# M460 register map
File version: 1.0
Registers are 32-bit, read-write, reset 0x0 unless marked. A register's access mark holds for its fields unless they carry their own. Offsets are from the block's base; [hi:lo] are bit positions; {n}, {i} and the like mark numbered series.

## RSA — CRYPTO Register Map
Base 0x40032B00
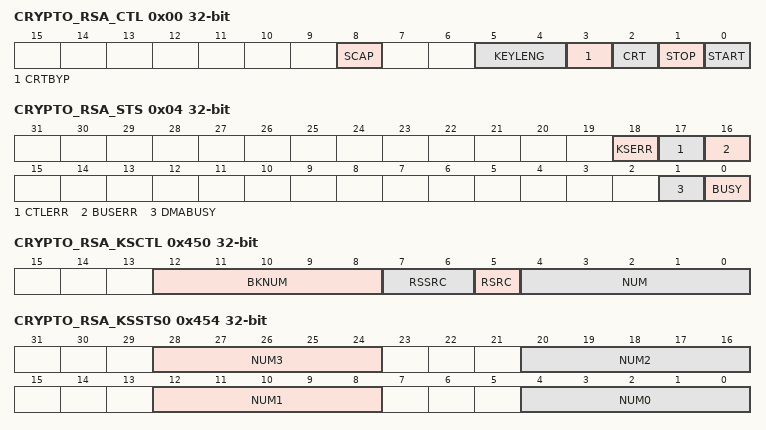
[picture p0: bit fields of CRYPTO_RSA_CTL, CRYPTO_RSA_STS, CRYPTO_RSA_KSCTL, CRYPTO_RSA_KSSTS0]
0x00 CRYPTO_RSA_CTL — RSA Control Register
  [8] SCAP — Side Channel Attack Protection Enable Control
    0=Side Channel Attack Protection Disabled; 1=Side Channel Attack Protection Enabled
  [5:4] KEYLENG — The Key Length of RSA Operation
    0=1024-bits; 1=2048-bits; 2=3072-bits; 3=4096-bits
  [3] CRTBYP — CRT Bypass Enable Control. CRT bypass is only used in CRT decryption with the same key. Note: If users want to decrypt repeatedly with the same key, they can execute CRT bypass mode after the first time CRT decryption (means the second time to the latest time), but they cannot set CRTBYP to 1 in non-CRT mode.
    0=CRT Bypass Disabled; 1=CRT Bypass Enabled
  [2] CRT — CRT Enable Control. CRT is only used in decryption with key length 2048, 3072,4096 bits.
    0=CRT Disabled; 1=CRT Enabled
  [1] STOP — RSA Accelerator Stop. This bit is always 0 when it is read back. Remember to clear RSA interrupt flag after stopping RSA accelerator.
    0=No effect; 1=Abort RSA accelerator and make it into initial state
  [0] START — RSA Accelerator Start. This bit is always 0 when it is read back. RSA accelerator will ignore this START signal when BUSY flag is 1.
    0=No effect; 1=Start RSA accelerator. BUSY flag will be set
0x04 CRYPTO_RSA_STS ro — RSA Status Register
  [18] KSERR — RSA Engine Access Key Store Error Flag
    0=No error; 1=Access error will stop RSA engine
  [17] CTLERR — RSA Control Register Error Flag. Note: If users use the error combination of control, even though they don't set START(CRYPTO_RSA_CTL[0]) to 1, CTLERR will still be set to 1.
    0=No error; 1=RSA control error. RSA will not start in the unsupported situation
  [16] BUSERR — RSA DMA Access Bus Error Flag
    0=No error; 1=Bus error will stop DMA operation and RSA accelerator
  [1] DMABUSY — RSA DMA Busy Flag
    0=RSA DMA is idle or finished; 1=RSA DMA is busy
  [0] BUSY — RSA Accelerator Busy Flag. Remember to clear RSA interrupt flag after RSA accelerator finished.
    0=The RSA accelerator is idle or finished; 1=The RSA accelerator is under processing and protects all registers
0x08 CRYPTO_RSA_SADDR0 — RSA DMA Source Address Register0
  [31:0] SADDR0 — RSA DMA Source Address Register0. The RSA accelerator supports DMA function to transfer the DATA and PARAMETER between SRAM memory space and RSA accelerator. This register is stored the address of RSA the Base of Exponentiation (M).
0x0C CRYPTO_RSA_SADDR1 — RSA DMA Source Address Register1
  [31:0] SADDR1 — RSA DMA Source Address Register1. The RSA accelerator supports DMA function to transfer the DATA and PARAMETER between SRAM memory space and RSA accelerator. This register is stored the address of RSA the Base of Modulus Operation (N).
0x10 CRYPTO_RSA_SADDR2 — RSA DMA Source Address Register2
  [31:0] SADDR2 — RSA DMA Source Address Register2. The RSA accelerator supports DMA function to transfer the DATA and PARAMETER between SRAM memory space and RSA accelerator. This register is stored the address of RSA the Exponent of Exponentiation (E).
0x14 CRYPTO_RSA_SADDR3 — RSA DMA Source Address Register3
  [31:0] SADDR3 — RSA DMA Source Address Register3. The RSA accelerator supports DMA function to transfer the DATA and PARAMETER between SRAM memory space and RSA accelerator. This register is stored the address of RSA the Factor of Modulus Operation (p).
0x18 CRYPTO_RSA_SADDR4 — RSA DMA Source Address Register4
  [31:0] SADDR4 — RSA DMA Source Address Register4. The RSA accelerator supports DMA function to transfer the DATA and PARAMETER between SRAM memory space and RSA accelerator. This register is stored the address of RSA the Factor of Modulus Operation (q).
0x1C CRYPTO_RSA_DADDR — RSA DMA Destination Address Register
  [31:0] DADDR — RSA DMA Destination Address Register. The RSA accelerator supports DMA function to transfer the DATA and PARAMETER between SRAM memory space and RSA accelerator. This register is stored the address of RSA DMA Destination Address Register (Ans).
{0x20+4i} CRYPTO_RSA_MADDR{i} (i=0..6) — RSA DMA Middle Address Register{i}
  [31:0] MADDR{i} — RSA DMA Middle Address Register{i}. The RSA accelerator supports DMA function to transfer the DATA and PARAMETER between SRAM memory space and RSA accelerator.
0x450 CRYPTO_RSA_KSCTL wo — RSA Key Control Register
  [12:8] BKNUM — Read Exponent Blind Key Number. The key number is sent to key store, and its destination always be the SRAM of key store. CPU cannot read the exponent blind key. Note: Use this key number, only when executing SCA protection but no-CRT mode. When allocate space of key store, key owner selection bits(KS_METADATA[18:16]) should be '010'.
  [7:6] RSSRC — Read Key Store Source
    0=Key is read from the SRAM of key store; 1=Key is read from the Flash of key store
  [5] RSRC — Read Key Source
    0=Key is read from RSA engine; 1=Key is read from key store
  [4:0] NUM — Read Key Number. The key number is sent to key store
0x454 CRYPTO_RSA_KSSTS0 — RSA Key Status Register 0
  [28:24] NUM3 — Key Number3. The key number is generated by key store, RSA can get or store the intermediate temporary value by key number in the key store while operating. Note: The size of this key as key length.
  [20:16] NUM2 — Key Number2. The key number is generated by key store, RSA can get or store the intermediate temporary value by key number in the key store while operating. Note: The size of this key as key length.
  [12:8] NUM1 — Key Number1. The key number is generated by key store, RSA can get complete q by key number in Key Store while operating. Note: The size of this key as half key length.
  [4:0] NUM0 — Key Number0. The key number is generated by key store, RSA can get complete p by key number in key store while operating. Note: The size of this key as half key length.
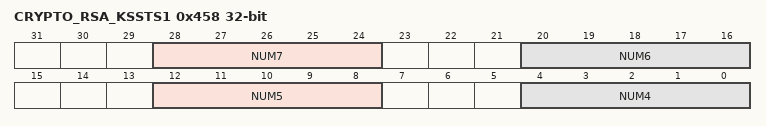
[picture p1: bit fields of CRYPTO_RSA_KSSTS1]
0x458 CRYPTO_RSA_KSSTS1 — RSA Key Status Register 1
  [28:24] NUM7 — Key Number7. The key number is generated by key store, RSA can get or store the intermediate temporary value by key number in key store while operating. Note: The size of this key as key length.
  [20:16] NUM6 — Key Number6. The key number is generated by key store, RSA can get or store the intermediate temporary value by key number in key store while operating. Note: The size of this key as key length.
  [12:8] NUM5 — Key Number5. The key number is generated by key store, RSA can get or store the intermediate temporary value by key number in key store while operating. Note: The size of this key as half key length.
  [4:0] NUM4 — Key Number4. The key number is generated by key store, RSA can get or store the intermediate temporary value by key number in key store while operating. Note: The size of this key as half key length.
